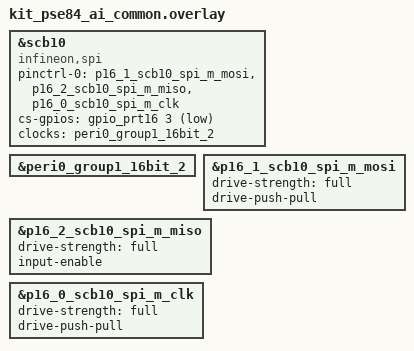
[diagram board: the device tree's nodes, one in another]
/*
 * SPDX-FileCopyrightText: <text>Copyright (c) 2026 Infineon Technologies AG,
 * or an affiliate of Infineon Technologies AG. All rights reserved.</text>
 *
 * SPDX-License-Identifier: Apache-2.0
 */

#define SPI_LOOPBACK_SLOW_HZ 3000000
#define SPI_LOOPBACK_FAST_HZ 3000000

spi_loopback: &scb10 {
	#address-cells = <1>;
	#size-cells = <0>;
	compatible = "infineon,spi";
	status = "okay";

	pinctrl-0 = <&p16_1_scb10_spi_m_mosi &p16_2_scb10_spi_m_miso &p16_0_scb10_spi_m_clk>;
	pinctrl-names = "default";
	cs-gpios = <&gpio_prt16 3 GPIO_ACTIVE_LOW>;

	clocks = <&peri0_group1_16bit_2>;
};

&peri0_group1_16bit_2 {
	status = "okay";
};

&p16_1_scb10_spi_m_mosi {
	drive-strength = "full";
	drive-push-pull;
};

&p16_2_scb10_spi_m_miso {
	drive-strength = "full";
	input-enable;
};

&p16_0_scb10_spi_m_clk {
	drive-strength = "full";
	drive-push-pull;
};

#include "../spi-loopback.dtsi"
